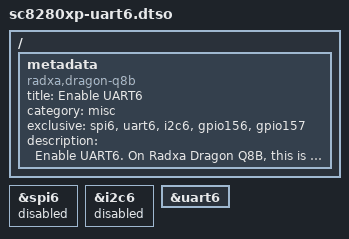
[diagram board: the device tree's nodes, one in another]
// SPDX-License-Identifier: BSD-3-Clause
/*
 * Copyright (c) 2026 Radxa Computer (Shenzhen) Co., Ltd.
 */

/dts-v1/;
/plugin/;

/ {
	metadata {
		title = "Enable UART6";
		compatible = "radxa,dragon-q8b";
		category = "misc";
		exclusive = "spi6", "uart6", "i2c6", "gpio156", "gpio157";
		description = "Enable UART6.
On Radxa Dragon Q8B, this is pin 32(tx), 29(rx).";
	};
};

&spi6 {
	status = "disabled";
};

&i2c6 {
	status = "disabled";
};

&uart6 {
	status = "okay";
};
